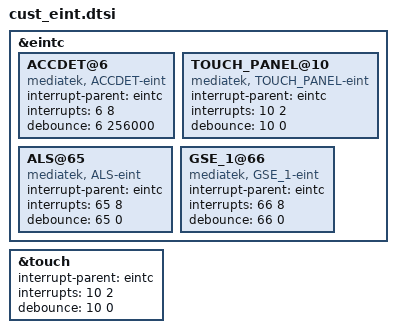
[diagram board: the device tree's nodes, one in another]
/*
 * Generated by MTK SP Drv_CodeGen Version 03.13.6  for MT6735. Copyright MediaTek Inc. (C) 2013.
 * Thu May 28 10:14:14 2015
 * Do Not Modify the File.
 */

/*************************
 * EINT DTSI File
*************************/

#include <dt-bindings/interrupt-controller/irq.h>
#include <dt-bindings/interrupt-controller/arm-gic.h>

&eintc {

	ACCDET@6 {
		compatible = "mediatek, ACCDET-eint";
		interrupt-parent = <&eintc>;
		interrupts = <6 8>;
		debounce = <6 256000>;
	};

	TOUCH_PANEL@10 {
		compatible = "mediatek, TOUCH_PANEL-eint";
		interrupt-parent = <&eintc>;
		interrupts = <10 2>;
		debounce = <10 0>;
	};

	ALS@65 {
		compatible = "mediatek, ALS-eint";
		interrupt-parent = <&eintc>;
		interrupts = <65 8>;
		debounce = <65 0>;
	};

	GSE_1@66 {
		compatible = "mediatek, GSE_1-eint";
		interrupt-parent = <&eintc>;
		interrupts = <66 8>;
		debounce = <66 0>;
	};
};
&touch {
	interrupt-parent = <&eintc>;
	interrupts = <10 2>;
	debounce = <10 0>;
};
